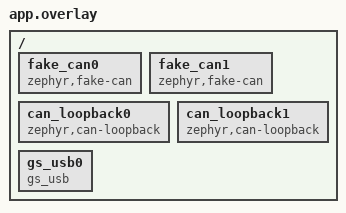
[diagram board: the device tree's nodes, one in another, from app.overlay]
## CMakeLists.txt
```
# SPDX-FileCopyrightText: Copyright (c) 2024-2026 Henrik Brix Andersen <henrik@brixandersen.dk>
#
# SPDX-License-Identifier: Apache-2.0

cmake_minimum_required(VERSION 3.28.0)
find_package(Zephyr REQUIRED HINTS $ENV{ZEPHYR_BASE})
project(host)

FILE(GLOB app_sources src/*.c)
target_sources(app PRIVATE ${app_sources})
```

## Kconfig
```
# SPDX-FileCopyrightText: Copyright (c) 2024-2026 Henrik Brix Andersen <henrik@brixandersen.dk>
#
# SPDX-License-Identifier: Apache-2.0

menu "Test suite for gs_usb"

config TEST_USB_MANUFACTURER
	string "USB device manufacturer string"
	default "CANnectivity"
	help
	  USB device manufacturer string.

config TEST_USB_PRODUCT
	string "USB device product string"
	default "CANnectivity gs_usb Test Suite"
	help
	  USB product string.

config TEST_USB_VID
	hex "USB device Vendor ID (VID)"
	default 0x1209
	help
	  USB device Vendor ID (VID).

config TEST_USB_PID
	hex "USB device Product ID (PID)"
	default 0x0001
	help
	  USB device Product ID (PID).

config TEST_USB_MAX_POWER
	int "USB device maximum power"
	default 125
	range 0 250
	help
	  USB maximum current draw in milliampere (mA) divided by 2.
	  A value of 125 results in a maximum current draw value of 250 mA.

endmenu

source "Kconfig.zephyr"
```

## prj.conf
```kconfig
# SPDX-FileCopyrightText: Copyright (c) 2024-2026 Henrik Brix Andersen <henrik@brixandersen.dk>
#
# SPDX-License-Identifier: Apache-2.0

CONFIG_TEST=y

CONFIG_LOG=y
CONFIG_UDC_DRIVER_LOG_LEVEL_WRN=y
CONFIG_USBD_LOG_LEVEL_WRN=y
CONFIG_USBD_GS_USB_LOG_LEVEL_DBG=y

CONFIG_SHELL=y

CONFIG_USB_DEVICE_STACK_NEXT=y

CONFIG_CAN=y
CONFIG_CAN_FD_MODE=y

CONFIG_USBD_GS_USB_MAX_CHANNELS=4
CONFIG_USBD_GS_USB_IDENTIFICATION=y
CONFIG_USBD_GS_USB_TIMESTAMP=y
CONFIG_USBD_GS_USB_TERMINATION=y
```

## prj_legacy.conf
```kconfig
# This is using the deprecated USB device stack
CONFIG_DEPRECATION_TEST=y

CONFIG_TEST=y

CONFIG_LOG=y
CONFIG_USB_DRIVER_LOG_LEVEL_ERR=y
CONFIG_USB_DEVICE_LOG_LEVEL_ERR=y
CONFIG_USB_DEVICE_GS_USB_LOG_LEVEL_DBG=y

CONFIG_SHELL=y

CONFIG_USB_DEVICE_STACK=y
CONFIG_USB_DEVICE_BOS=y
CONFIG_USB_DEVICE_INITIALIZE_AT_BOOT=n

CONFIG_CAN=y
CONFIG_CAN_FD_MODE=y

CONFIG_USB_DEVICE_GS_USB_MAX_CHANNELS=4
CONFIG_USB_DEVICE_GS_USB_IDENTIFICATION=y
CONFIG_USB_DEVICE_GS_USB_TIMESTAMP=y
CONFIG_USB_DEVICE_GS_USB_TERMINATION=y
```

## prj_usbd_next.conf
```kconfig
CONFIG_TEST=y

CONFIG_LOG=y
CONFIG_UDC_DRIVER_LOG_LEVEL_WRN=y
CONFIG_USBD_LOG_LEVEL_WRN=y
CONFIG_USBD_GS_USB_LOG_LEVEL_DBG=y

CONFIG_SHELL=y

CONFIG_USB_DEVICE_STACK_NEXT=y

CONFIG_CAN=y
CONFIG_CAN_FD_MODE=y

CONFIG_USBD_GS_USB_MAX_CHANNELS=4
CONFIG_USBD_GS_USB_IDENTIFICATION=y
CONFIG_USBD_GS_USB_TIMESTAMP=y
CONFIG_USBD_GS_USB_TERMINATION=y
```

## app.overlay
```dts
/*
 * SPDX-FileCopyrightText: Copyright (c) 2022-2026 Henrik Brix Andersen <henrik@brixandersen.dk>
 *
 * SPDX-License-Identifier: Apache-2.0
 */

/ {
	fake_can0: fake_can0 {
		status = "okay";
		compatible = "zephyr,fake-can";
	};

	fake_can1: fake_can1 {
		status = "okay";
		compatible = "zephyr,fake-can";
	};

	can_loopback0: can_loopback0 {
		status = "okay";
		compatible = "zephyr,can-loopback";
	};

	can_loopback1: can_loopback1 {
		status = "okay";
		compatible = "zephyr,can-loopback";
	};

	gs_usb0: gs_usb0 {
		compatible = "gs_usb";
	};
};
```

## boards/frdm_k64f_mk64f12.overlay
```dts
/*
 * SPDX-FileCopyrightText: Copyright (c) 2025-2026 Henrik Brix Andersen <henrik@brixandersen.dk>
 *
 * SPDX-License-Identifier: Apache-2.0
 */

#include "../app.overlay"

&flexcan0 {
	status = "disabled";
};
```

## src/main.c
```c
/*
 * SPDX-FileCopyrightText: Copyright (c) 2024-2026 Henrik Brix Andersen <henrik@brixandersen.dk>
 *
 * SPDX-License-Identifier: Apache-2.0
 */

#include <zephyr/fff.h>
#include <zephyr/device.h>
#include <zephyr/devicetree.h>
#include <zephyr/drivers/can.h>
#include <zephyr/drivers/can/can_fake.h>
#include <zephyr/logging/log.h>
#include <zephyr/sys/util.h>

#include <cannectivity/usb/class/gs_usb.h>

#include "test.h"

LOG_MODULE_REGISTER(main, LOG_LEVEL_DBG);

DEFINE_FFF_GLOBALS;

#define USER_DATA 0x12345678
#define TIMESTAMP 0xdeadbeef

static int fake_can_get_capabilities_delegate(const struct device *dev, can_mode_t *cap)
{
	*cap = CAN_MODE_NORMAL | CAN_MODE_FD;

	return 0;
}

static int fake_can_get_state_delegate(const struct device *dev, enum can_state *state,
				       struct can_bus_err_cnt *err_cnt)
{
	*state = CAN_STATE_ERROR_PASSIVE;

	err_cnt->tx_err_cnt = 128;
	err_cnt->rx_err_cnt = 96;

	return 0;
}

static int fake_can_set_timing_delegate(const struct device *dev, const struct can_timing *timing)
{
	LOG_DBG("%s: sjw = %u, prop_seg = %u, phase_seg1 = %u, phase_seg2 = %u, "
		"prescaler = %u", dev->name, timing->sjw, timing->prop_seg, timing->phase_seg1,
		timing->phase_seg2, timing->prescaler);

	return 0;
}

static int fake_can_set_timing_data_delegate(const struct device *dev,
					     const struct can_timing *timing_data)
{
	LOG_DBG("%s: sjw = %u, prop_seg = %u, phase_seg1 = %u, phase_seg2 = %u, "
		"prescaler = %u", dev->name, timing_data->sjw, timing_data->prop_seg,
		timing_data->phase_seg1, timing_data->phase_seg2, timing_data->prescaler);

	return 0;
}

static int fake_can_start_delegate(const struct device *dev)
{
	LOG_DBG("%s: start", dev->name);

	return 0;
}

static int fake_can_stop_delegate(const struct device *dev)
{
	LOG_DBG("%s: stop", dev->name);

	return 0;
}

static int fake_can_set_mode_delegate(const struct device *dev, can_mode_t mode)
{
	LOG_DBG("%s: mode = 0x%08x", dev->name, mode);

	return 0;
}

static int event_cb(const struct device *dev, uint16_t ch, enum gs_usb_event event, void *user_data)
{
	uint32_t ud = POINTER_TO_UINT(user_data);

	switch (event) {
	case GS_USB_EVENT_CHANNEL_STARTED:
		LOG_DBG("dev = %s, ch = %u, started = 1, user_data = 0x%08x", dev->name, ch, ud);
		break;
	case GS_USB_EVENT_CHANNEL_STOPPED:
		LOG_DBG("dev = %s, ch = %u, started = 0, user_data = 0x%08x", dev->name, ch, ud);
		break;
	case GS_USB_EVENT_CHANNEL_ERROR_ON:
		LOG_DBG("dev = %s, ch = %u, error = 1, user_data = 0x%08x", dev->name, ch, ud);
		break;
	case GS_USB_EVENT_CHANNEL_ERROR_OFF:
		LOG_DBG("dev = %s, ch = %u, error = 0, user_data = 0x%08x", dev->name, ch, ud);
		break;
	case GS_USB_EVENT_CHANNEL_ACTIVITY_RX:
		LOG_DBG("dev = %s, ch = %u, rx activity = 1, user_data = 0x%08x", dev->name, ch,
			ud);
		break;
	case GS_USB_EVENT_CHANNEL_ACTIVITY_TX:
		LOG_DBG("dev = %s, ch = %u, tx activity = 1, user_data = 0x%08x", dev->name, ch,
			ud);
		break;
	case GS_USB_EVENT_CHANNEL_IDENTIFY_ON:
		LOG_DBG("dev = %s, ch = %u, identify = 1, user_data = 0x%08x", dev->name, ch, ud);
		break;
	case GS_USB_EVENT_CHANNEL_IDENTIFY_OFF:
		LOG_DBG("dev = %s, ch = %u, identify = 0, user_data = 0x%08x", dev->name, ch, ud);
		break;
	}

	return 0;
}

static int set_termination_cb(const struct device *dev, uint16_t ch, bool terminate,
			      void *user_data)
{
	uint32_t ud = POINTER_TO_UINT(user_data);

	LOG_DBG("dev = %s, ch = %u, terminate = %u, user_data = 0x%08x", dev->name, ch, terminate,
		ud);

	return 0;
}

static int get_termination_cb(const struct device *dev, uint16_t ch, bool *terminated,
			      void *user_data)
{
	uint32_t ud = POINTER_TO_UINT(user_data);

	*terminated = (ch % 2 == 0) ? true : false;
	LOG_DBG("dev = %s, ch = %u, terminated = %u, user_data = 0x%08x", dev->name, ch,
		*terminated, ud);

	return 0;
}

static int timestamp_get_cb(const struct device *dev, uint32_t *timestamp, void *user_data)
{
	uint32_t ud = POINTER_TO_UINT(user_data);

	*timestamp = TIMESTAMP;
	LOG_DBG("dev = %s, timestamp = 0x%08x, user_data = 0x%08x", dev->name, *timestamp, ud);

	return 0;
}

static const struct gs_usb_ops gs_usb_ops = {
	.timestamp = timestamp_get_cb,
	.event = event_cb,
	.set_termination = set_termination_cb,
	.get_termination = get_termination_cb,
};

int main(void)
{
	const struct device *gs_usb = DEVICE_DT_GET(DT_NODELABEL(gs_usb0));
	const struct device *channels[] = {
		DEVICE_DT_GET(DT_NODELABEL(fake_can0)),
		DEVICE_DT_GET(DT_NODELABEL(fake_can1)),
		DEVICE_DT_GET(DT_NODELABEL(can_loopback0)),
		DEVICE_DT_GET(DT_NODELABEL(can_loopback1)),
	};
	int err;
	int i;

	fake_can_get_capabilities_fake.custom_fake = fake_can_get_capabilities_delegate;
	fake_can_get_state_fake.custom_fake = fake_can_get_state_delegate;
	fake_can_set_timing_fake.custom_fake = fake_can_set_timing_delegate;
	fake_can_set_timing_data_fake.custom_fake = fake_can_set_timing_data_delegate;
	fake_can_start_fake.custom_fake = fake_can_start_delegate;
	fake_can_stop_fake.custom_fake = fake_can_stop_delegate;
	fake_can_set_mode_fake.custom_fake = fake_can_set_mode_delegate;

	if (!device_is_ready(gs_usb)) {
		LOG_ERR("gs_usb USB device not ready");
		return 0;
	}

	for (i = 0; i < ARRAY_SIZE(channels); i++) {
		if (!device_is_ready(channels[i])) {
			LOG_ERR("CAN controller channel %d not ready", i);
			return 0;
		}
	}

	err = gs_usb_register(gs_usb, channels, ARRAY_SIZE(channels), &gs_usb_ops,
			      UINT_TO_POINTER(USER_DATA));
	if (err != 0U) {
		LOG_ERR("failed to register gs_usb (err %d)", err);
		return 0;
	}

	err = test_usb_init();
	if (err != 0) {
		LOG_ERR("failed to initialize USB (err %d)", err);
		return 0;
	}
}
```

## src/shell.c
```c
/*
 * SPDX-FileCopyrightText: Copyright (c) 2024-2026 Henrik Brix Andersen <henrik@brixandersen.dk>
 *
 * SPDX-License-Identifier: Apache-2.0
 */

#include <zephyr/shell/shell.h>

static int cmd_gs_usb_vid(const struct shell *sh, size_t argc, char **argv)
{
	ARG_UNUSED(argc);
	ARG_UNUSED(argv);

	shell_print(sh, "USB VID: 0x%04x", CONFIG_TEST_USB_VID);

	return 0;
}

static int cmd_gs_usb_pid(const struct shell *sh, size_t argc, char **argv)
{
	ARG_UNUSED(argc);
	ARG_UNUSED(argv);

	shell_print(sh, "USB PID: 0x%04x", CONFIG_TEST_USB_PID);

	return 0;
}

SHELL_STATIC_SUBCMD_SET_CREATE(sub_gs_usb_cmds,
	SHELL_CMD(vid, NULL,
		"Get USB VID\n"
		"Usage: gs_usb vid",
		cmd_gs_usb_vid),
	SHELL_CMD(pid, NULL,
		"Get USB PID\n"
		"Usage: gs_usb pid",
		cmd_gs_usb_pid),
	SHELL_SUBCMD_SET_END
);

SHELL_CMD_REGISTER(gs_usb, &sub_gs_usb_cmds, "gs_usb test commands", NULL);
```

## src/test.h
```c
/*
 * SPDX-FileCopyrightText: Copyright (c) 2024-2026 Henrik Brix Andersen <henrik@brixandersen.dk>
 *
 * SPDX-License-Identifier: Apache-2.0
 */

#ifndef CANNECTIVITY_TEST_SUBSYS_USB_GS_USB_TEST_H_
#define CANNECTIVITY_TEST_SUBSYS_USB_GS_USB_TEST_H_

int test_usb_init(void);

#endif /* CANNECTIVITY_TEST_SUBSYS_USB_GS_USB_TEST_H_ */
```

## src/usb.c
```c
/*
 * SPDX-FileCopyrightText: Copyright (c) 2024-2026 Henrik Brix Andersen <henrik@brixandersen.dk>
 *
 * SPDX-License-Identifier: Apache-2.0
 */

#include <zephyr/logging/log.h>
#include <zephyr/sys/byteorder.h>
#include <zephyr/usb/usbd.h>

#include "test.h"

LOG_MODULE_REGISTER(usb, LOG_LEVEL_DBG);

#define GS_USB_CLASS_INSTANCE_NAME "gs_usb_0"

static const struct usb_bos_capability_lpm bos_cap_lpm = {
	.bLength = sizeof(struct usb_bos_capability_lpm),
	.bDescriptorType = USB_DESC_DEVICE_CAPABILITY,
	.bDevCapabilityType = USB_BOS_CAPABILITY_EXTENSION,
	.bmAttributes = 0UL,
};

USBD_DEVICE_DEFINE(usbd, DEVICE_DT_GET(DT_NODELABEL(zephyr_udc0)), CONFIG_TEST_USB_VID,
		   CONFIG_TEST_USB_PID);

USBD_DESC_LANG_DEFINE(lang);
USBD_DESC_MANUFACTURER_DEFINE(mfr, CONFIG_TEST_USB_MANUFACTURER);
USBD_DESC_PRODUCT_DEFINE(product, CONFIG_TEST_USB_PRODUCT);
USBD_DESC_SERIAL_NUMBER_DEFINE(sn);
USBD_DESC_CONFIG_DEFINE(fs_config_desc, "Full-Speed Configuration");
USBD_DESC_CONFIG_DEFINE(hs_config_desc, "High-Speed Configuration");

USBD_CONFIGURATION_DEFINE(fs_config, 0U, CONFIG_TEST_USB_MAX_POWER, &fs_config_desc);
USBD_CONFIGURATION_DEFINE(hs_config, 0U, CONFIG_TEST_USB_MAX_POWER, &hs_config_desc);

USBD_DESC_BOS_DEFINE(usbext, sizeof(bos_cap_lpm), &bos_cap_lpm);

int test_usb_init(void)
{
	int err;

	err = usbd_add_descriptor(&usbd, &lang);
	if (err != 0) {
		LOG_ERR("failed to add language descriptor (err %d)", err);
		return err;
	}

	err = usbd_add_descriptor(&usbd, &mfr);
	if (err != 0) {
		LOG_ERR("failed to add manufacturer descriptor (err %d)", err);
		return err;
	}

	err = usbd_add_descriptor(&usbd, &product);
	if (err != 0) {
		LOG_ERR("failed to add product descriptor (%d)", err);
		return err;
	}

	err = usbd_add_descriptor(&usbd, &sn);
	if (err != 0) {
		LOG_ERR("failed to add S/N descriptor (err %d)", err);
		return err;
	}

	if (usbd_caps_speed(&usbd) == USBD_SPEED_HS) {
		err = usbd_add_configuration(&usbd, USBD_SPEED_HS, &hs_config);
		if (err != 0) {
			LOG_ERR("failed to add high-speed configuration (err %d)", err);
			return err;
		}

		err = usbd_register_class(&usbd, GS_USB_CLASS_INSTANCE_NAME, USBD_SPEED_HS, 1);
		if (err != 0) {
			LOG_ERR("failed to register high-speed class instance (err %d)", err);
			return err;
		}

		err = usbd_device_set_code_triple(&usbd, USBD_SPEED_HS, 0, 0, 0);
		if (err != 0) {
			LOG_ERR("failed to set high-speed code triple (err %d)", err);
			return err;
		}

		err = usbd_device_set_bcd_usb(&usbd, USBD_SPEED_HS, USB_SRN_2_0_1);
		if (err != 0) {
			LOG_ERR("failed to set high-speed bcdUSB (err %d)", err);
			return err;
		}
	}

	err = usbd_add_configuration(&usbd, USBD_SPEED_FS, &fs_config);
	if (err != 0) {
		LOG_ERR("failed to add full-speed configuration (err %d)", err);
		return err;
	}

	err = usbd_register_class(&usbd, GS_USB_CLASS_INSTANCE_NAME, USBD_SPEED_FS, 1);
	if (err != 0) {
		LOG_ERR("failed to register full-speed class instance (err %d)", err);
		return err;
	}

	err = usbd_device_set_code_triple(&usbd, USBD_SPEED_FS, 0, 0, 0);
	if (err != 0) {
		LOG_ERR("failed to set full-speed code triple (err %d)", err);
		return err;
	}

	err = usbd_device_set_bcd_usb(&usbd, USBD_SPEED_FS, USB_SRN_2_0_1);
	if (err != 0) {
		LOG_ERR("failed to set full-speed bcdUSB (err %d)", err);
		return err;
	}

	err = usbd_add_descriptor(&usbd, &usbext);
	if (err != 0) {
		LOG_ERR("failed to add USB 2.0 extension descriptor (err %d)", err);
		return err;
	}

	err = usbd_init(&usbd);
	if (err != 0) {
		LOG_ERR("failed to initialize USB device support (err %d)", err);
		return err;
	}

	err = usbd_enable(&usbd);
	if (err != 0) {
		LOG_ERR("failed to enable USB device");
		return err;
	}

	return 0;
}
```
